# psoc4hvpaspm10 register map
Vendor: Infineon Technologies; Series: PSOC4HVPASPM10; File version: 1.0
CPU: CM0PLUS r0p1, little endian, MPU, no FPU, VTOR, 2 interrupt priority bits, 32 interrupts
Registers are 32-bit, read-write, reset 0x0 unless marked. A register's access mark holds for its fields unless they carry their own. Offsets are from the block's base; [hi:lo] are bit positions; {n}, {i} and the like mark numbered series.

## HVSS — High Voltage Subsystem
Base 0x40060000
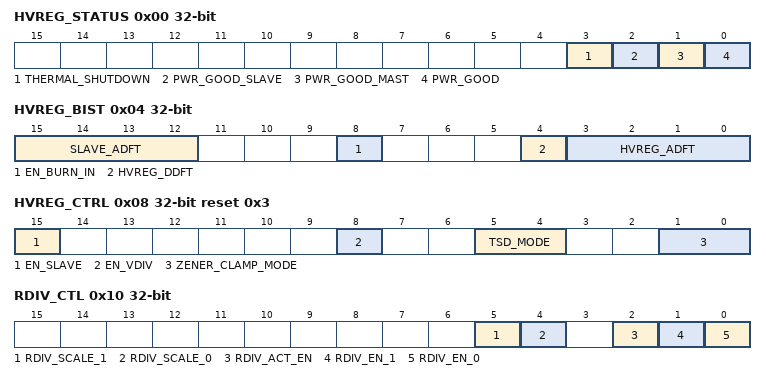
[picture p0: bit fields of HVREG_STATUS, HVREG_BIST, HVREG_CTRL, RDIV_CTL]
0x00 HVREG_STATUS ro
  [3] THERMAL_SHUTDOWN — Thermal Shutdown Active
  [2] PWR_GOOD_SLAVE — Slave Power Good
  [1] PWR_GOOD_MAST — Master Power Good
  [0] PWR_GOOD — High if regulator is settled and operating within normal limits
0x04 HVREG_BIST
  [15:12] SLAVE_ADFT — Controls ADFT switches
    0=NORMAL (Normal operation, amuxbus_a=Z); 1=RSVD_1 (N/A); 2=RSVD_2 (N/A); 3=RSVD_3 (N/A); 4=SLAVE_IDRIVE (Slave driver current monitor (3uA nominal)); 5=SLAVE_TSD_GATE (Slave TSD NMOS gate voltage); 6=RSVD_6 (N/A); 7=SLAVE_ZENER_GATE (Slave Zener enable gate voltage); 8=SLAVE_ILIM (Slave Current limit mirror); 9=SLAVE_ILIM2 (Slave Current limit2 monitor); {v}=RSVD_{v} (N/A) (v=10..15)
  [8] EN_BURN_IN — Enable burn-in test mode with Vccd(1.8V) domain
  [4] HVREG_DDFT — Enable HVREG DDFT outputs to DDFT interface when '1' (PG on ddft0, '0' on ddft1)
  [3:0] HVREG_ADFT — Controls ADFT switches
    0=NORMAL (Normal operation, amuxbus_a=Z); 1=BIAS_CIRCUIT_CURRENT_MONITOR (Vbias monitor); 2=IREF1P4V (N/A); 3=IBIAS (N/A); 4=MAST_IDRIVE (N/A); 5=MAST_TSD_GATE (N/A); 6=MAST_TSD_DIODE (N/A); 7=MAST_ZENER_GATE (N/A); 8=MAST_ILIM (N/A); 9=MAST_ILIM2 (N/A); 10=TSD_VTH_VOTAGE_DET (N/A); 11=TSD_VTH_VOTAGE_REL (N/A); 12=TSD_OUT_VCCD (N/A); 13=TSD_OUT_VCCD2 (N/A); 14=RSVD_14 (N/A); 15=RSVD_15 (N/A)
0x08 HVREG_CTRL reset 0x3 — HVREG Control
  [15] EN_SLAVE — Enable slave
  [8] EN_VDIV — Enable Vbat Voltage divider
  [5:4] TSD_MODE — Controls thermal shutdown mode
    0=KEEP_REGULATORS_ON_FOR_TSD (Keep Vdd on for TSD event (LIN turns off)); 1=TURN_OFF_REGULATORS_ON_TSD (Turn off Vdd and LIN on TSD event); 2=RSVD_2 (N/A); 3=TURN_OFF_TSD (Turn off TSD circuit)
  [1:0] ZENER_CLAMP_MODE — Controls zener clamp mode
    0=CLAMP_NOT_PRESENT_0 (Zener disabled); 1=CLAMP_NOT_PRESENT_1 (Zener disabled); 2=ZENER_CLAMP_PRESENT (Zener enabled); 3=ZENER_CLAMP_DIODE_PRESENT (Zener and diode enabled)
0x10 RDIV_CTL — Resistor Attenuator Control
  [5] RDIV_SCALE_1 — VS1 attenuation 0=16X attenuation 1=24X attenuation
  [4] RDIV_SCALE_0 — VS0 attenuation 0=16X attenuation 1=24X attenuation
  [2] RDIV_ACT_EN — Power modes where RDIV is enabled 0=Enable in Active and Deep-Sleep modes 1=Enable in Active mode only
  [1] RDIV_EN_1 — Enable VS1 0=Disabled 1=Enabled during power modes selected by RDIV_ACT_EN
  [0] RDIV_EN_0 — Enable VS0 0=Disabled 1=Enabled during power modes selected by RDIV_ACT_EN
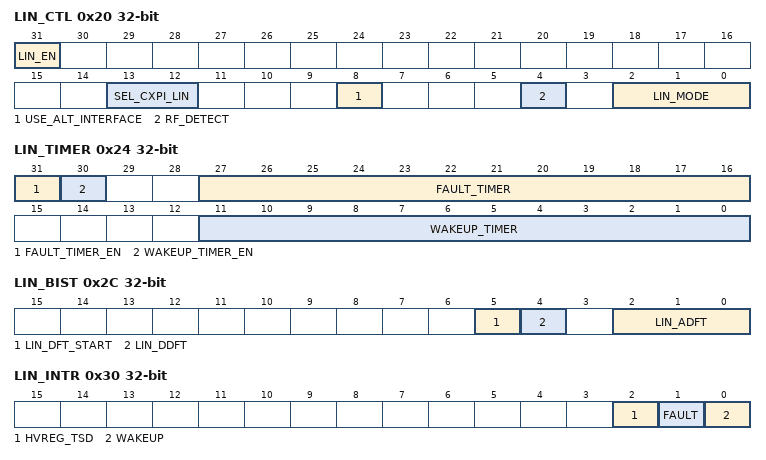
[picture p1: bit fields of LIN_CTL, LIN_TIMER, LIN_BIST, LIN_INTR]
0x20 LIN_CTL — LIN PHY Control
  [31] LIN_EN — Master enable of the LIN/CXPI interface. 0=Interface is reset and LIN pin is in Hi-Z state 1=Enable the LIN interface
  [13:12] SEL_CXPI_LIN — Selects LIN or CXPI interface. Bit 1 selects between LIN and CXPI, Bit 0 selects between CXPI master and slave
    0=LIN_PHY_0 (Operates as LIN interface); 1=LIN_PHY_1 (Operates as LIN interface); 2=CXPI_MASTER (Operates as CXPI master); 3=CXPI_SLAVE (Operates as CXPI slave)
  [8] USE_ALT_INTERFACE — Selects Primary or Alternate interface for PHY. The primary use is to enable compliance testing by directly manipulating the PHY interface through GPIOs. 0 = Primary interface (connected to internal LIN/CXPI controller through HSIOM) 1 = Alternate interface (connected to GPIOs through HSIOM)
  [4] RF_DETECT — Renamed from SL_ROUND. 0=off; 1=on, reduce impact on LIN driver from incoming EMI.
  [2:0] LIN_MODE — Controls LIN mode
    0=DISABLED (OFF (TX off, Rx off, Bias Circuits Off), LIN pin recessive); 1=SLEEP (TX off, RX on, LIN pin recessive (typically used in deep-sleep)); 2=STANDBY (TX off, RX off, Bias circuits on (faster turn-on, not normally used)); 3=DIAGNOSIS (TX on, RX on, TX w/weak pull-down (broken wire detect diag)); 4=NORMAL_1_0 (TX on, RX on, 1.0V/us TX edge rate, may not meet all parameters of LIN spec at some operating conditions); 5=NORMAL_1_5 (TX on, RX on, 1.5V/us TX edge rate, meets all parameters of LIN spec); 6=NORMAL_2_0 (TX on, RX on, 2.0V/us TX edge rate, may not meet all parameters of LIN spec at some operating conditions); 7=FAST (Fast mode (non-lin compliant, up to 100kb/s capable))
0x24 LIN_TIMER — LIN Timer Control
  [31] FAULT_TIMER_EN — Dominant state fault timer is running, required for full LIN compatibility
  [30] WAKEUP_TIMER_EN — Wakeup timer is running, required for full LIN compatibility if using Deep-sleep power mode
  [27:16] FAULT_TIMER — Number of CLK_LF edges before fault interrupt is triggered
  [11:0] WAKEUP_TIMER — Number of CLK_LF edges before wakeup interrupt is triggered
0x28 LIN_STATUS ro
  [0] LIN_RXD — Current state of LIN pin, except when LIN_CTL.LIN_MODE is 0 or 2, when RXD = 1.
0x2C LIN_BIST — LIN BIST Control
  [5] LIN_DFT_START — Delay line input
  [4] LIN_DDFT — Enable LIN DDFT outputs to DDFT interface ddft1 = dft<1>, ddft0 = dft<0>
  [2:0] LIN_ADFT — Enables Test Modes
    0=NORMAL (Normal Operation (DFT disabled), amuxbus_a=Z, dft<1:0>=0); 1=CURRENT_MONITOR_LWAVE (amuxbus_a=Iwave (PMOS drain), dft<1:0>=0); 2=VOLTAGE_MONITOR_ERRBUFF (amuxbus_a=ErrBuff, dft<1:0>=0); 3=WEAK_OUTFET (OUTFET = 1/10, (amuxbus_a=Z, dft<1:0>=0)); 4=CURRENT_MONITOR_FOR_BIAS_CKT (amuxbus_a=Ibias monitor (PMOS drain), dft<1:0>=0); 5=SL_ROUND (0=Normal, 1=More moderate (rounded) edge for lower EMI); 6=DDFT_OSC (amuxbus_a = Z dft<1> = LIN_DFT_START, dft<0> = LIN_OSC); 7=DDFT_DELAY (amuxbus_a = Z dft<1> = LIN_DFT_START, dft<0> = LIN_DELAY)
0x30 LIN_INTR — HVSS Interrupt Request Register
  [2] HVREG_TSD write-1-clears — Thermal Shutdown Detected
  [1] FAULT write-1-clears — Interface asserted state for too long (dominant state timeout)
  [0] WAKEUP write-1-clears — Master asserted dominant state wakeup (wakeup timer timeout)
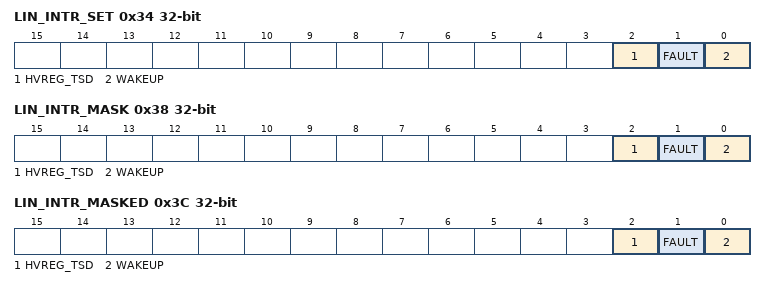
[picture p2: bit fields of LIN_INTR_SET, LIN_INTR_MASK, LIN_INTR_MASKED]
0x34 LIN_INTR_SET — HVSS Interrupt set register
  [2] HVREG_TSD write-1-sets — Write with '1' to set corresponding bit in interrupt request register.
  [1] FAULT write-1-sets — Write with '1' to set corresponding bit in interrupt request register.
  [0] WAKEUP write-1-sets — Write with '1' to set corresponding bit in interrupt request register.
0x38 LIN_INTR_MASK — HVSS Interrupt mask register
  [2] HVREG_TSD — Mask bit for corresponding bit in interrupt request register.
  [1] FAULT — Mask bit for corresponding bit in interrupt request register.
  [0] WAKEUP — Mask bit for corresponding bit in interrupt request register.
0x3C LIN_INTR_MASKED ro — HVSS Interrupt masked register
  [2] HVREG_TSD — Logical and of corresponding request and mask bits.
  [1] FAULT — Logical and of corresponding request and mask bits.
  [0] WAKEUP — Logical and of corresponding request and mask bits.
0x40 HVSS_DDFT — HVSS DDFT Control
  [0] LSOUT_DDFT — Enable LSOUT DDFT output to DDFT interface ddft1 = lsout_ddft, ddft0 = 0
0xFF00 HVREG_TRIM — HVREG Master Trim (Output Voltage)
  [5:0] TRIM — Trim for VDDD output.
0xFF04 LIN_TRIM — LIN Trim Settings
  [7:0] SLEW_CTL
0xFF10 HVREG_TRIM_VREF — HVREG Vref Trim
  [5:0] VREF_CTL — Vref Trim
0xFF14 HVREG_TRIM_VREF_TC — HVREG Vref Output Voltage temp-co Trim
  [5:0] TC_CTL — Vref Temperature Trim
0xFF18 HVREG_TRIM_TSD — HVREG TSD detection temperatureTrim
  [5:0] TSD_CTL — TSD Trim
0xFF1C HVREG_TRIM_S — HVREG Slave Trim (Output Voltage)
  [5:0] TRIM — Trim for VDDD output.
